# Template register map
Vendor: VendorName Co.Ltd; Series: SeriesName; File version: 1.2
CPU: CM7 r0p1, little endian, MPU, FPU, 4 interrupt priority bits
Registers are 32-bit, read-write, no defined reset value unless marked. A register's access mark holds for its fields unless they carry their own. Offsets are from the block's base; [hi:lo] are bit positions; {n}, {i} and the like mark numbered series; 'fields as' and 'values as' point back to an identical list.

## EPWM1 — Enhanced Pulse Width Modulator 1
Base 0x40000000
Same registers: EPWM{n} {0x3FFFF000+0x1000*n} (n=2..18)
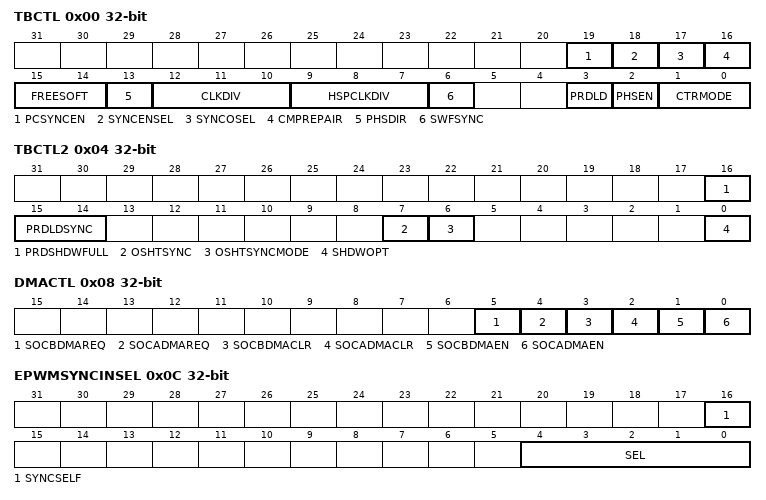
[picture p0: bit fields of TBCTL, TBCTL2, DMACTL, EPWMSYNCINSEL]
0x00 TBCTL — EPWM time base control register
  [19] PCSYNCEN — EPWM PCSYNCEN bit: PWM chopper synchronization enable
  [18] SYNCENSEL — EPWM SYNCENSEL bit: synchronization load enable selection
  [17] SYNCOSEL — EPWM SYNCOSEL bit: EPWM synchronization output enable selection
  [16] CMPREPAIR — EPWM CMPREPAIR bit: PWM wave adjust when phase loading or comparation value updating
  [15:14] FREESOFT — EPWM FREESOFT[1:0] bit: emulation mode bits
  [13] PHSDIR — EPWM PHSDIR bit: phase direction bit
  [12:10] CLKDIV — EPWM CLKDIV[2:0] bit: time base clock prescale bits
  [9:7] HSPCLKDIV — EPWM HSPCLKDIV[2:0] bit: high speed time base clock prescale bits
  [6] SWFSYNC wo — EPWM SWFSYNC bit: software forced sync pulse
  [3] PRDLD — EPWM PRDLD bit: active period register load from shadow select
  [2] PHSEN — EPWM PHSEN bit: counter value load from phase register enable
  [1:0] CTRMODE — EPWM CTRMODE[1:0] bit: counter mode
0x04 TBCTL2 — EPWM time base control register 2
  [16] PRDSHDWFULL ro — EPWM PRDSHDWFULL bit: shadow to active period register full status flag
  [15:14] PRDLDSYNC — EPWM PRDLDSYNC[1:0] bit: shadow to active period register load on sync event
  [7] OSHTSYNC wo — EPWM OSHTSYNC bit: oneshot sync bit
  [6] OSHTSYNCMODE — EPWM OSHTSYNCMODE bit: oneshot sync enable bit
  [0] SHDWOPT — EPWM SHDWOPT bit: counter load period register option
0x08 DMACTL — EPWM DMA register
  [5] SOCBDMAREQ ro — EPWM SOCBDMAREQ bit: SOCBDMA request
  [4] SOCADMAREQ ro — EPWM SOCADMAREQ bit: SOCADMA request
  [3] SOCBDMACLR wo — EPWM SOCBDMACLR bit: SOCBDMA request software clear
  [2] SOCADMACLR wo — EPWM SOCADMACLR bit: SOCADMA request software clear
  [1] SOCBDMAEN — EPWM SOCBDMAEN bit: SOCBDMA enable
  [0] SOCADMAEN — EPWM SOCADMAEN bit: SOCADMA enable
0x0C EPWMSYNCINSEL — EPWM synchronization source selection register
  [16] SYNCSELF — EPWM SYNCSELF bit: EPWMxSYNOUT source sync oneself enable
  [4:0] SEL — EPWM SEL[4:0] bit: EPWMxSYNCI source select
0x10 TBCTR — EPWM time base register
  [15:0] TBCTR — EPWM TBCTR[15:0] bit: time base counter register
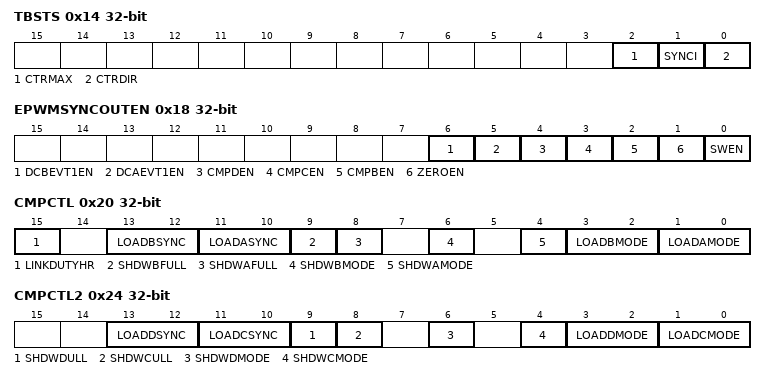
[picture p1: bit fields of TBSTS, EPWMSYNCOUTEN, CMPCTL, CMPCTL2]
0x14 TBSTS — EPWM time base state register
  [2] CTRMAX — EPWM CTRMAX bit: time-base counter max latched status bit
  [1] SYNCI — EPWM SYNCI bit: input synchronization latched status bit
  [0] CTRDIR ro — EPWM CTRDIR bit: time base counter direction status bit
0x18 EPWMSYNCOUTEN — EPWM synchronization output enable register
  [6] DCBEVT1EN — EPWM DCBEVT1EN bit: DCBEVT1.sync event enable
  [5] DCAEVT1EN — EPWM DCAEVT1EN bit: DCAEVT1.sync event enable
  [4] CMPDEN — EPWM CMPDEN bit: enable the TBCTR=CMPD event
  [3] CMPCEN — EPWM CMPCEN bit: enable the TBCTR=CMPC event
  [2] CMPBEN — EPWM CMPBEN bit: enable the TBCTR=CMPB event
  [1] ZEROEN — EPWM ZEROEN bit: enable the TBCTR=0x0000 event
  [0] SWEN — EPWM SWEN bit: TBCTL.SWFSYNC event enable
0x1C TBCTL3 — EPWM time base control register 3
  [0] OSSFRCEN — EPWM OSSFRCEN bit: determines which bit sets the EPWMxSYNCOUT one shot latch
0x20 CMPCTL — EPWM compare control register
  [15] LINKDUTYHR — EPWM LINKDUTYHR bit: CMPAHR and CMPBHR register linking
  [13:12] LOADBSYNC — EPWM LOADBSYNC[1:0] bit: shadow to active CMPB register load on SYNC event
  [11:10] LOADASYNC — EPWM LOADASYNC[1:0] bit: shadow to active CMPA register load on SYNC event
  [9] SHDWBFULL ro — EPWM SHDWBFULL bit: CMPB shadow register full status flag
  [8] SHDWAFULL ro — EPWM SHDWAFULL bit: CMPA shadow register full status flag
  [6] SHDWBMODE — EPWM SHDWBMODE bit: CMPB register operating mode
  [4] SHDWAMODE — EPWM SHDWAMODE bit: CMPA register operating mode
  [3:2] LOADBMODE — EPWM LOADBMODE[1:0] bit: CMPB load from shadow select mode
  [1:0] LOADAMODE — EPWM LOADAMODE[1:0] bit: CMPA load from shadow select mode
0x24 CMPCTL2 — EPWM compare control register 2
  [13:12] LOADDSYNC — EPWM LOADDSYNC[1:0] bit: shadow to active CMPD register load on SYNC event
  [11:10] LOADCSYNC — EPWM LOADCSYNC[1:0] bit: shadow to active CMPC register load on SYNC event
  [9] SHDWDULL ro — EPWM SHDWDULL bit: CMPD shadow register full status flag
  [8] SHDWCULL ro — EPWM SHDWCULL bit: CMPC shadow register full status flag
  [6] SHDWDMODE — EPWM SHDWDMODE bit: CMPD register operating mode
  [4] SHDWCMODE — EPWM SHDWCMODE bit: CMPC register operating mode
  [3:2] LOADDMODE — EPWM LOADDMODE[1:0] bit: CMPD load from shadow select mode
  [1:0] LOADCMODE — EPWM LOADCMODE[1:0] bit: CMPC load from shadow select mode
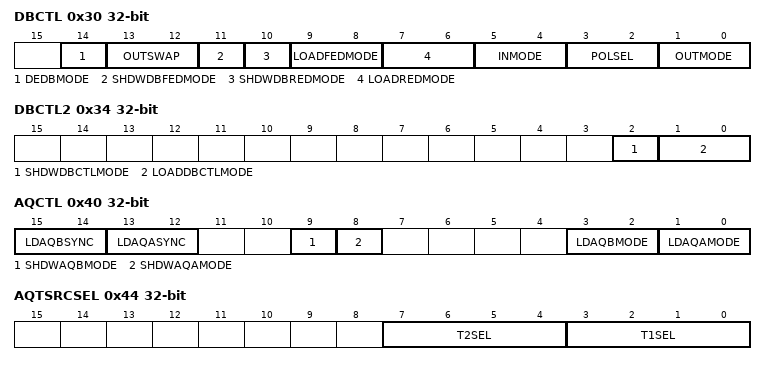
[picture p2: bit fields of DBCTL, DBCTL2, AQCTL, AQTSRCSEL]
0x30 DBCTL — EPWM dead time register
  [14] DEDBMODE — EPWM DEDBMODE bit: dead band dual-edge B mode control
  [13:12] OUTSWAP — EPWM OUTSWAP[1:0] bit: dead band output swap control
  [11] SHDWDBFEDMODE — EPWM SHDWDBFEDMODE bit: FED dead-band load mode
  [10] SHDWDBREDMODE — EPWM SHDWDBREDMODE bit: RED dead-band load mode
  [9:8] LOADFEDMODE — EPWM LOADFEDMODE[1:0] bit: active DBFED load from shadow select mode
  [7:6] LOADREDMODE — EPWM LOADREDMODE[1:0] bit: active DBRED load from shadow select mode
  [5:4] INMODE — EPWM INMODE[1:0] bit: dead-band input mode control
  [3:2] POLSEL — EPWM POLSEL[1:0] bit: polarity select control
  [1:0] OUTMODE — EPWM OUTMODE[1:0] bit: dead-band output mode control
0x34 DBCTL2 — EPWM dead time register 2
  [2] SHDWDBCTLMODE — EPWM SHDWDBCTLMODE bit: DBCTL load mode
  [1:0] LOADDBCTLMODE — EPWM LOADDBCTLMODE[1:0] bit: active DBCTL load from shadow select mode
0x40 AQCTL — EPWM action limitation control register
  [15:14] LDAQBSYNC — EPWM LDAQBSYNC[1:0] bit: shadow to active AQCTLB register load on SYNC event
  [13:12] LDAQASYNC — EPWM LDAQASYNC[1:0] bit: shadow to active AQCTLA register load on SYNC event
  [9] SHDWAQBMODE — EPWM SHDWAQBMODE bit: action qualifier B register operating mode
  [8] SHDWAQAMODE — EPWM SHDWAQAMODE bit: action qualifier A register operating mode
  [3:2] LDAQBMODE — EPWM LDAQBMODE[1:0] bit: active action qualifier B load from shadow select mode
  [1:0] LDAQAMODE — EPWM LDAQAMODE[1:0] bit: active action qualifier A load from shadow select mode
0x44 AQTSRCSEL — EPWM action limitation trigger source selection register
  [7:4] T2SEL — EPWM T2SEL[3:0] bit: T2 event source select bits
  [3:0] T1SEL — EPWM T1SEL[3:0] bit: T1 event source select bits
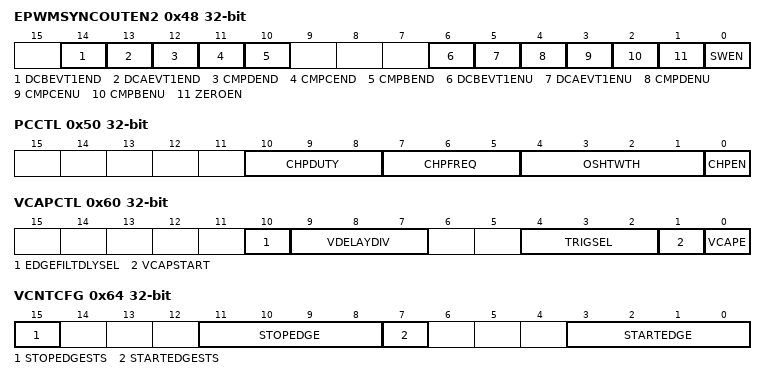
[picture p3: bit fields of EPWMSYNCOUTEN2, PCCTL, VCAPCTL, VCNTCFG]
0x48 EPWMSYNCOUTEN2 — EPWM synchronization output enable register 2
  [14] DCBEVT1END — EPWM DCBEVT1END bit: DCBEVT1.sync event end
  [13] DCAEVT1END — EPWM DCAEVT1END bit: DCAEVT1.sync event end
  [12] CMPDEND — EPWM CMPDEND bit: the TBCTR=CMPD event end
  [11] CMPCEND — EPWM CMPCEND bit: the TBCTR=CMPC event end
  [10] CMPBEND — EPWM CMPBEND bit: the TBCTR=CMPB event end
  [6] DCBEVT1ENU — EPWM DCBEVT1ENU bit: DCBEVT1.sync event enable
  [5] DCAEVT1ENU — EPWM DCAEVT1ENU bit: DCAEVT1.sync event enable
  [4] CMPDENU — EPWM CMPDENU bit: the TBCTR=CMPD event enable
  [3] CMPCENU — EPWM CMPCENU bit: the TBCTR=CMPC event enable
  [2] CMPBENU — EPWM CMPBENU bit: the TBCTR=CMPB event enable
  [1] ZEROEN — EPWM ZEROEN bit: enable the TBCTR=0x0000 event
  [0] SWEN — EPWM SWEN bit: TBCTL.SWFSYNC event enable
0x50 PCCTL — EPWM chopper control register
  [10:8] CHPDUTY — EPWM CHPDUTY[2:0] bit: chopping clock duty cycle
  [7:5] CHPFREQ — EPWM CHPFREQ[2:0] bit: chopping clock frequency division
  [4:1] OSHTWTH — EPWM OSHTWTH[3:0] bit: oneshot pulse width
  [0] CHPEN — EPWM CHPEN bit: PWM-chopping enable
0x60 VCAPCTL — EPWM valley capture control register
  [10] EDGEFILTDLYSEL — EPWM EDGEFILTDLYSEL bit: valley switching mode delay selection
  [9:7] VDELAYDIV — EPWM VDELAYDIV[2:0] bit: valley delay mode divide enable
  [4:2] TRIGSEL — EPWM TRIGSEL[2:0] bit: status of numbered of captured events
  [1] VCAPSTART wo — EPWM VCAPSTART bit: valley capture start control
  [0] VCAPE — EPWM VCAPE bit: valley capture enable bit
0x64 VCNTCFG — EPWM valley counter control register
  [15] STOPEDGESTS ro — EPWM STOPEDGESTS bit: stop edge status bit
  [11:8] STOPEDGE — EPWM STOPEDGE[3:0] bit: counter stop edge selection
  [7] STARTEDGESTS ro — EPWM STARTEDGESTS bit: start edge status bit
  [3:0] STARTEDGE — EPWM STARTEDGE[3:0] bit: counter start edge selection
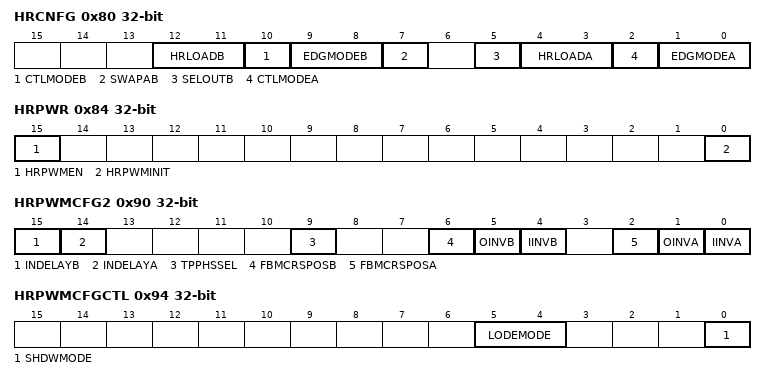
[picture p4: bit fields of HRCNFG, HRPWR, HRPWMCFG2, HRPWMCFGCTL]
0x80 HRCNFG — EPWM HRPWM control register
  [12:11] HRLOADB — EPWM HRLOADB[1:0] bit: shadow mode bit B
  [10] CTLMODEB — EPWM CTLMODEB bit: control mode bits B
  [9:8] EDGMODEB — EPWM EDGMODEB[1:0] bit: edge mode bits B
  [7] SWAPAB — EPWM SWAPAB bit: swap ePWM A & B output signals
  [5] SELOUTB — EPWM SELOUTB bit: EPWMxB output select bit
  [4:3] HRLOADA — EPWM HRLOADA[1:0] bit: shadow mode bit A
  [2] CTLMODEA — EPWM CTLMODEA bit: control mode bits A
  [1:0] EDGMODEA — EPWM EDGMODEA[1:0] bit: edge mode bits A
0x84 HRPWR — EPWM HRPWM enable register
  [15] HRPWMEN — EPWM HRPWMEN bit: high precision PWM function enable
  [0] HRPWMINIT — EPWM HRPWMINIT bit: HRPWM initialize
0x8C TBPRDHR — EPWM high-precision period register
  [5:0] TBPRDHR — EPWM TBPRDHR[5:0] bit: period high precision value
0x90 HRPWMCFG2 — EPWM HRPWM config register 2
  [15] INDELAYB — EPWM INDELAYB bit: channel B input or delay EPWM signal selection
  [14] INDELAYA — EPWM INDELAYA bit: channel A input or delay EPWM signal selection
  [9] TPPHSSEL — EPWM TPPHSSEL bit: period high-precision channel feedback signal selection
  [6] FBMCRSPOSB — EPWM FBMCRSPOSB bit: EPWMxB high-precision channel feedback signal rising edge selection
  [5] OINVB — EPWM OINVB bit: EPWMxB high-precision channel output signal inversion selection
  [4] IINVB — EPWM IINVB bit: EPWMxB high-precision channel input signal inversion selection
  [2] FBMCRSPOSA — EPWM FBMCRSPOSA bit: EPWMxA high-precision channel feedback signal rising edge selection
  [1] OINVA — EPWM OINVA bit: EPWMxA high-precision channel output signal inversion selection
  [0] IINVA — EPWM IINVA bit: EPWMxA high-precision channel input signal inversion selection
0x94 HRPWMCFGCTL — EPWM HRPWM config register
  [5:4] LODEMODE — EPWM LODEMODE[1:0] bit: loading mode select
  [0] SHDWMODE — EPWM SHDWMODE bit: TBPRDHR register operate mode
0x98 HRMSTEP — EPWM HRPWM step register
  [5:0] HRMSTEP — EPWM HRMSTEP[5:0] bit: high precision PWM ware MEP step register
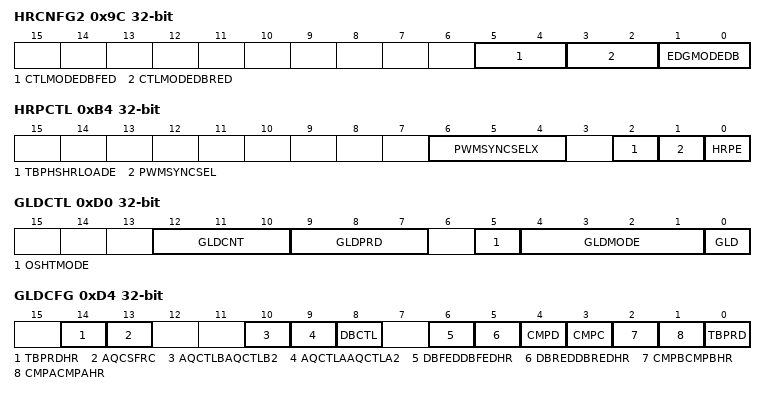
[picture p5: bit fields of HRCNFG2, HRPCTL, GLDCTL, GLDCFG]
0x9C HRCNFG2 — EPWM HRPWM control register 2
  [5:4] CTLMODEDBFED — EPWM CTLMODEDBFED[1:0] bit: DBFEDHR shadow mode control bit
  [3:2] CTLMODEDBRED — EPWM CTLMODEDBRED[1:0] bit: DBREDHR shadow mode control bit
  [1:0] EDGMODEDB — EPWM EDGMODEDB[1:0] bit: dead zone high precision edge mode bits
0xB4 HRPCTL — EPWM HRPWM period control register
  [6:4] PWMSYNCSELX — EPWM PWMSYNCSELX[2:0] bit: extended selection bits for EPWMSYNCPER
  [2] TBPHSHRLOADE — EPWM TBPHSHRLOADE bit: TBPHSHR load enable
  [1] PWMSYNCSEL — EPWM PWMSYNCSEL bit: PWMSYNC source select bit
  [0] HRPE — EPWM HRPE bit: high resolution period enable bit
0xD0 GLDCTL — EPWM global load control register
  [12:10] GLDCNT ro — EPWM GLDCNT[2:0] bit: global load strobe counter register
  [9:7] GLDPRD — EPWM GLDPRD[2:0] bit: global load strobe period select register
  [5] OSHTMODE — EPWM OSHTMODE bit: one shot load mode control bit
  [4:1] GLDMODE — EPWM GLDMODE[3:0] bit: global load pulse selection for shadow to active mode reloads
  [0] GLD — EPWM GLD bit: global shadow to active load event control
0xD4 GLDCFG — EPWM global load config register
  [14] TBPRDHR — EPWM TBPRDHR bit: global load event configuration for TBPRDHR
  [13] AQCSFRC — EPWM AQCSFRC bit: global load event configuration for AQCSFRC
  [10] AQCTLBAQCTLB2 — EPWM AQCTLBAQCTLB2 bit: global load event configuration for AQCTLBAQCTLB2
  [9] AQCTLAAQCTLA2 — EPWM AQCTLAAQCTLA2 bit: global load event configuration for AQCTLAAQCTLA2
  [8] DBCTL — EPWM DBCTL bit: global load event configuration for DBCTL
  [6] DBFEDDBFEDHR — EPWM DBFEDDBFEDHR bit: global load event configuration for DBFEDDBFEDHR
  [5] DBREDDBREDHR — EPWM DBREDDBREDHR bit: global load event configuration for DBREDDBREDHR
  [4] CMPD — EPWM CMPD bit: global load event configuration for CMPD
  [3] CMPC — EPWM CMPC bit: global load event configuration for CMPC
  [2] CMPBCMPBHR — EPWM CMPBCMPBHR bit: global load event configuration for CMPBCMPBHR
  [1] CMPACMPAHR — EPWM CMPACMPAHR bit: global load event configuration for CMPACMPAHR
  [0] TBPRD — EPWM TBPRD bit: global load event configuration for TBPRD
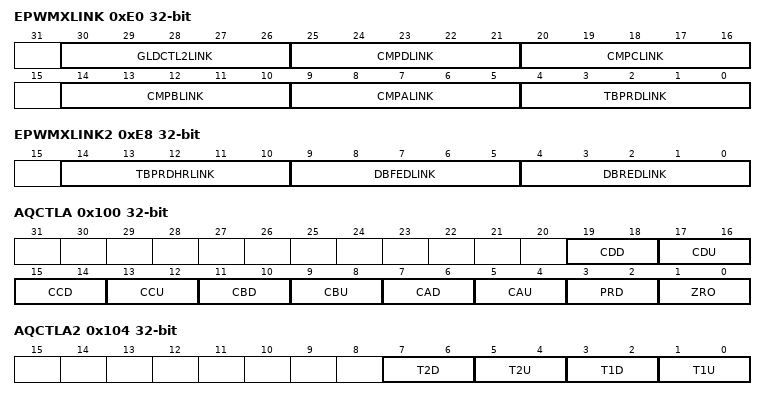
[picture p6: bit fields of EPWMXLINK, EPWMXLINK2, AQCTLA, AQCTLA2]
0xE0 EPWMXLINK — EPWM x linker register
  [30:26] GLDCTL2LINK — EPWM GLDCTL2LINK[4:0] bit: GLDCTL2 link bits
  [25:21] CMPDLINK — EPWM CMPDLINK[4:0] bit: CMPD link bits
  [20:16] CMPCLINK — EPWM CMPCLINK[4:0] bit: CMPC link bits
  [14:10] CMPBLINK — EPWM CMPBLINK[4:0] bit: CMPB link bits
  [9:5] CMPALINK — EPWM CMPALINK[4:0] bit: CMPA link bits
  [4:0] TBPRDLINK — EPWM TBPRDLINK[4:0] bit: TBPRD link bits
0xE8 EPWMXLINK2 — EPWM x linker register 2
  [14:10] TBPRDHRLINK — EPWM TBPRDHRLINK[4:0] bit: TBPRDHR link bits
  [9:5] DBFEDLINK — EPWM DBFEDLINK[4:0] bit: DBFED_DBFEDHR link bits
  [4:0] DBREDLINK — EPWM DBREDLINK[4:0] bit: DBRED_DBREDHR link bits
0x100 AQCTLA — EPWM x A channel limition control register
  [19:18] CDD — EPWM CDD[1:0] bit: action when TBCTR=CMPD on down count
  [17:16] CDU — EPWM CDU[1:0] bit: action when TBCTR=CMPD on up count
  [15:14] CCD — EPWM CCD[1:0] bit: action when TBCTR=CMPC on down count
  [13:12] CCU — EPWM CCU[1:0] bit: action when TBCTR=CMPC on up count
  [11:10] CBD — EPWM CBD[1:0] bit: action when TBCTR=CMPB on down count
  [9:8] CBU — EPWM CBU[1:0] bit: action when TBCTR=CMPB on up count
  [7:6] CAD — EPWM CAD[1:0] bit: action when TBCTR=CMPA on down count
  [5:4] CAU — EPWM CAU[1:0] bit: action when TBCTR=CMPA on up count
  [3:2] PRD — EPWM PRD[1:0] bit: action when TBCTR=TBPRD
  [1:0] ZRO — EPWM ZRO[1:0] bit: action when TBCTR=0
0x104 AQCTLA2 — EPWM x A channel limition control register 2
  [7:6] T2D — EPWM T2D[1:0] bit: action when event occurs on T2 in DOWN-count
  [5:4] T2U — EPWM T2U[1:0] bit: action when event occurs on T2 in UP-count
  [3:2] T1D — EPWM T1D[1:0] bit: action when event occurs on T1 in DOWN-count
  [1:0] T1U — EPWM T1U[1:0] bit: action when event occurs on T1 in UP-count
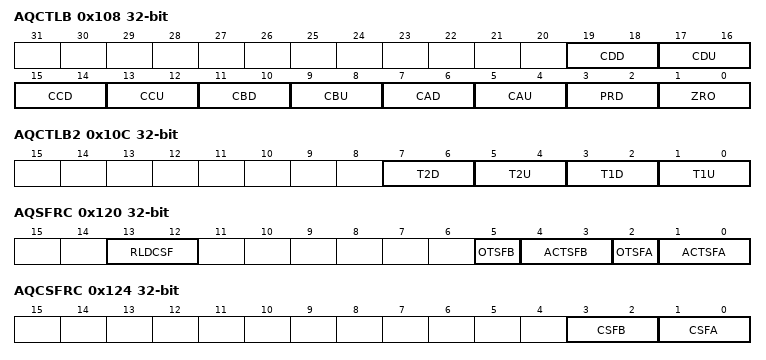
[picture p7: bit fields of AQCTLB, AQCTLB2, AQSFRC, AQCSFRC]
0x108 AQCTLB — EPWM x B channel limition control register
  fields as AQCTLA
0x10C AQCTLB2 — EPWM x B channel limition control register 2
  fields as AQCTLA2
0x120 AQSFRC — EPWM software-forced action limitation register
  [13:12] RLDCSF — EPWM RLDCSF[1:0] bit: AQCSFRC active register reload from shadow options
  [5] OTSFB — EPWM OTSFB bit: one-time software forced event on output B
  [4:3] ACTSFB — EPWM ACTSFB[1:0] bit: action when one-time software force B is invoked
  [2] OTSFA — EPWM OTSFA bit: one-time software forced event on output A
  [1:0] ACTSFA — EPWM ACTSFA[1:0] bit: action when one-time software force A is invoked
0x124 AQCSFRC — EPWM sequential software-forced action limitation register
  [3:2] CSFB — EPWM CSFB[1:0] bit: continuous software force on output B
  [1:0] CSFA — EPWM CSFA[1:0] bit: continuous software force on output A
0x140 DBREDHR — EPWM dead time rising edge high-precision delay register
  [13:8] DBREDHR — EPWM DBREDHR[5:0] bit: dead band rising edge delay high resolution bits
0x144 DBRED — EPWM dead time rising edge delay register 1
  [13:0] DBRED — EPWM DBRED[13:0] bit: rising edge delay value
0x148 DBFEDHR — EPWM dead time falling edge high-precision delay register
  [13:8] DBFEDHR — EPWM DBFEDHR[5:0] bit: dead band falling edge delay high resolution bits
0x14C DBFED — EPWM dead time falling edge delay register 1
  [13:0] DBFED — EPWM DBFED[13:0] bit: falling edge delay count
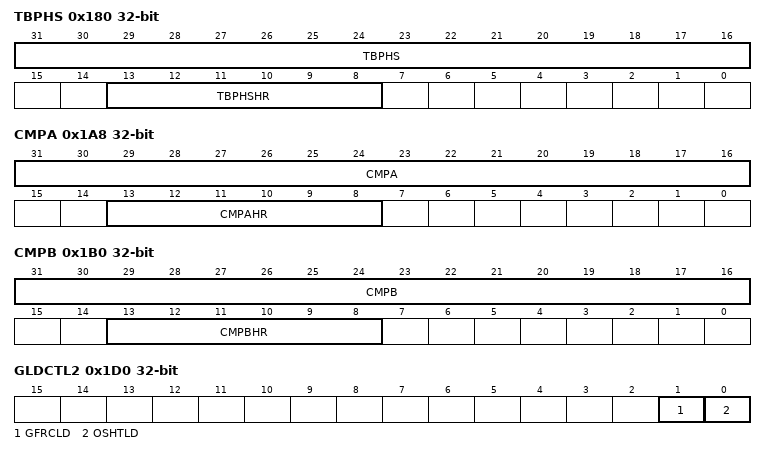
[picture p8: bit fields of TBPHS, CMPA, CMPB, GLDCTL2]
0x180 TBPHS — EPWM time base phase offset register
  [31:16] TBPHS — EPWM TBPHS[15:0] bit: phase offset register
  [13:8] TBPHSHR — EPWM TBPHSHR[5:0] bit: phase offset high resolution register
0x18C TBPRD — EPWM time base period register
  [15:0] TBPRD — EPWM TBPRD[15:0] bit: time base period register
0x1A8 CMPA — EPWM compare A register
  [31:16] CMPA — EPWM CMPA[15:0] bit: compare A register
  [13:8] CMPAHR — EPWM CMPAHR[5:0] bit: compare A HRPWM extension register
0x1B0 CMPB — EPWM compare B register
  [31:16] CMPB — EPWM CMPB[15:0] bit: compare B register
  [13:8] CMPBHR — EPWM CMPBHR[5:0] bit: compare B high resolution bits
0x1BC CMPC — EPWM compare C register
  [15:0] CMPC — EPWM CMPC[15:0] bit: compare C register
0x1C4 CMPD — EPWM compare D register
  [15:0] CMPD — EPWM CMPD[15:0] bit: compare D register
0x1D0 GLDCTL2 — EPWM global load control register 2
  [1] GFRCLD — EPWM GFRCLD bit: force load event in one shot mode
  [0] OSHTLD — EPWM OSHTLD bit: enable reload event in one shot mode
0x1DC SWVDELVAL — EPWM valley software delay register
  [15:0] SWDELVAL — EPWM SWDELVAL[15:0] bit: software valley delay value register
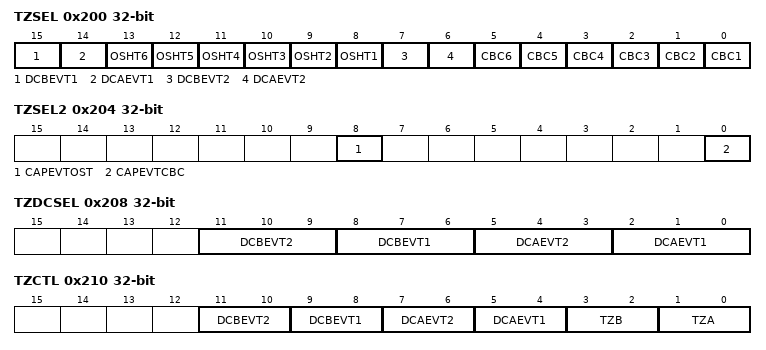
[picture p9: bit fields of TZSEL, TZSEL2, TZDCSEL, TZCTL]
0x200 TZSEL — EPWM trip zone selection register
  [15] DCBEVT1 — EPWM DCBEVT1 bit: digital compare output B event 1 select
  [14] DCAEVT1 — EPWM DCAEVT1 bit: digital compare output A event 1 select
  [n+7] OSHT{n} (n=1..6) — EPWM OSHT{n} bit: trip-zone {n} enable select as one-shot trip event source
  [7] DCBEVT2 — EPWM DCBEVT2 bit: digital compare output B event 2 select
  [6] DCAEVT2 — EPWM DCAEVT2 bit: digital compare output A event 2 select
  [n-1] CBC{n} (n=1..6) — EPWM CBC{n} bit: trip-zone {n} enable select as CBC trip event source
0x204 TZSEL2 — EPWM trip zone selection register 2
  [8] CAPEVTOST — EPWM CAPEVTOST bit: CAPEVT OST select
  [0] CAPEVTCBC — EPWM CAPEVTCBC bit: CAPEVT CBC mode select
0x208 TZDCSEL — EPWM trip zone digital compare register
  [11:9] DCBEVT2 — EPWM DCBEVT2[2:0] bit: digital compare output B event 2 selection
  [8:6] DCBEVT1 — EPWM DCBEVT1[2:0] bit: digital compare output B event 1 selection
  [5:3] DCAEVT2 — EPWM DCAEVT2[2:0] bit: digital compare output A event 2 selection
  [2:0] DCAEVT1 — EPWM DCAEVT1[2:0] bit: digital compare output A event 1 selection
0x210 TZCTL — EPWM trip zone control register
  [11:10] DCBEVT2 — EPWM DCBEVT2[1:0] bit: digital compare output B event 2 action on EPWMxB
  [9:8] DCBEVT1 — EPWM DCBEVT1[1:0] bit: digital compare output B event 1 action on EPWMxB
  [7:6] DCAEVT2 — EPWM DCAEVT2[1:0] bit: digital compare output A event 2 action on EPWMxA
  [5:4] DCAEVT1 — EPWM DCAEVT1[1:0] bit: digital compare output A event 1 action on EPWMxA
  [3:2] TZB — EPWM TZB[1:0] bit: TZ1 to TZ6 trip action on EPWMxB
  [1:0] TZA — EPWM TZA[1:0] bit: TZ1 to TZ6 trip action on EPWMxA
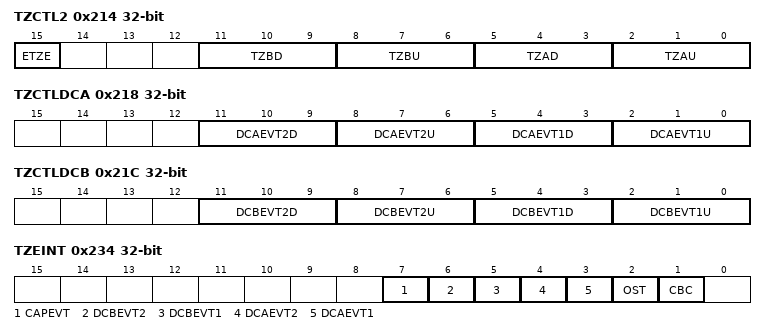
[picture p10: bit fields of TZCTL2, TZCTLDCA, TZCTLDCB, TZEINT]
0x214 TZCTL2 — EPWM trip zone control register 2
  [15] ETZE — EPWM ETZE bit: TZCTL2 enable
  [11:9] TZBD — EPWM TZBD[2:0] bit: TZ1 to TZ6 trip action on EPWMxB while count direction is DOWN
  [8:6] TZBU — EPWM TZBU[2:0] bit: TZ1 to TZ6 trip action on EPWMxB while count direction is UP
  [5:3] TZAD — EPWM TZAD[2:0] bit: TZ1 to TZ6 trip action on EPWMxA while count direction is DOWN
  [2:0] TZAU — EPWM TZAU[2:0] bit: TZ1 to TZ6 trip action on EPWMxA while count direction is UP
0x218 TZCTLDCA — EPWM trip zone digital compare A register
  [11:9] DCAEVT2D — EPWM DCAEVT2D[2:0] bit: DCAEVT2 action on EPWMxA while count direction is DOWN
  [8:6] DCAEVT2U — EPWM DCAEVT2U[2:0] bit: DCAEVT2 action on EPWMxA while count direction is UP
  [5:3] DCAEVT1D — EPWM DCAEVT1D[2:0] bit: DCAEVT1 action on EPWMxA while count direction is DOWN
  [2:0] DCAEVT1U — EPWM DCAEVT1U[2:0] bit: DCAEVT1 action on EPWMxA while count direction is UP
0x21C TZCTLDCB — EPWM trip zone digital compare B register
  [11:9] DCBEVT2D — EPWM DCBEVT2D[2:0] bit: DCBEVT2 action on EPWMxB while count direction is DOWN
  [8:6] DCBEVT2U — EPWM DCBEVT2U[2:0] bit: DCBEVT2 action on EPWMxB while count direction is UP
  [5:3] DCBEVT1D — EPWM DCBEVT1D[2:0] bit: DCBEVT1 action on EPWMxB while count direction is DOWN
  [2:0] DCBEVT1U — EPWM DCBEVT1U[2:0] bit: DCBEVT1 action on EPWMxB while count direction is UP
0x234 TZEINT — EPWM trip zone interrupt enable register
  [7] CAPEVT — EPWM CAPEVT bit: capture event interrupt enable
  [6] DCBEVT2 — EPWM DCBEVT2 bit: digital compare output B event 2 interrupt enable
  [5] DCBEVT1 — EPWM DCBEVT1 bit: digital compare output B event 1 interrupt enable
  [4] DCAEVT2 — EPWM DCAEVT2 bit: digital compare output A event 2 interrupt enable
  [3] DCAEVT1 — EPWM DCAEVT1 bit: digital compare output A event 1 interrupt enable
  [2] OST — EPWM OST bit: trip-zone one-shot interrupt enable
  [1] CBC — EPWM CBC bit: trip-zone cycle-by-cycle interrupt enable
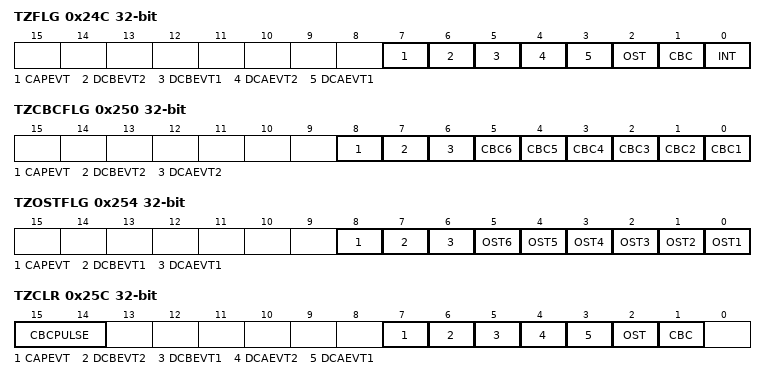
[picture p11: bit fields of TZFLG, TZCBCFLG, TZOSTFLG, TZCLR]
0x24C TZFLG ro — EPWM trip zone flag register
  [7] CAPEVT — EPWM CAPEVT bit: latched status flag for capture event
  [6] DCBEVT2 — EPWM DCBEVT2 bit: latched status flag for digital compare output B event 2
  [5] DCBEVT1 — EPWM DCBEVT1 bit: latched status flag for digital compare output B event 1
  [4] DCAEVT2 — EPWM DCAEVT2 bit: latched status flag for digital compare output A event 2
  [3] DCAEVT1 — EPWM DCAEVT1 bit: latched status flag for digital compare output A event 1
  [2] OST — EPWM OST bit: latched status flag for A one-shot trip event
  [1] CBC — EPWM CBC bit: latched status flag for cycle-by-cycle trip event
  [0] INT — EPWM INT bit: latched trip interrupt status flag
0x250 TZCBCFLG ro — EPWM trip zone CBC flag register
  [8] CAPEVT — EPWM CAPEVT bit: latched status flag for capture event
  [7] DCBEVT2 — EPWM DCBEVT2 bit: latched status flag for digital compare B output event 2 trip latch
  [6] DCAEVT2 — EPWM DCAEVT2 bit: latched status flag for digital compare A output event 2 trip latch
  [n-1] CBC{n} (n=1..6) — EPWM CBC{n} bit: latched status flag for CBC{n} trip latch
0x254 TZOSTFLG ro — EPWM trip zone OST flag register
  [8] CAPEVT — EPWM CAPEVT bit: latched status flag for capture event
  [7] DCBEVT1 — EPWM DCBEVT1 bit: latched status flag for digital compare B output event 1 trip latch
  [6] DCAEVT1 — EPWM DCAEVT1 bit: latched status flag for digital compare A output event 1 trip latch
  [n-1] OST{n} (n=1..6) — EPWM OST{n} bit: latched status flag for OST{n} trip latch
0x25C TZCLR — EPWM trip zone flag clear register
  [15:14] CBCPULSE — EPWM CBCPULSE[1:0] bit: clear pulse for cycle-by-cycle trip latch
  [7] CAPEVT wo — EPWM CAPEVT bit: clear flag for capture event
  [6] DCBEVT2 wo — EPWM DCBEVT2 bit: clear flag for digital compare output B event 2
  [5] DCBEVT1 wo — EPWM DCBEVT1 bit: clear flag for digital compare output B event 1
  [4] DCAEVT2 wo — EPWM DCAEVT2 bit: clear flag for digital compare output A event 2
  [3] DCAEVT1 wo — EPWM DCAEVT1 bit: clear flag for digital compare output A event 1
  [2] OST wo — EPWM OST bit: clear flag for one-shot trip latch
  [1] CBC wo — EPWM CBC bit: clear flag for cycle-by-cycle trip latch
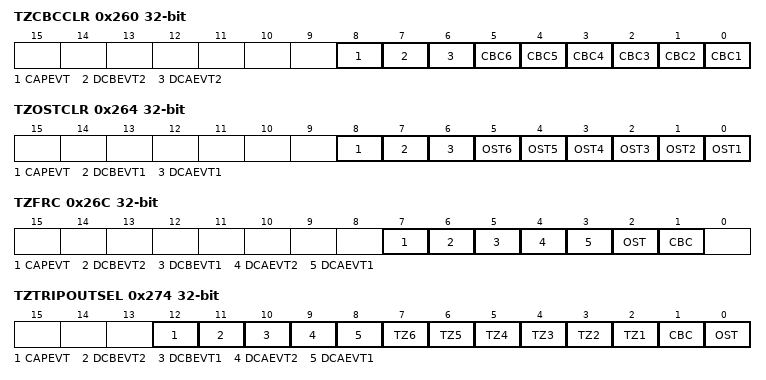
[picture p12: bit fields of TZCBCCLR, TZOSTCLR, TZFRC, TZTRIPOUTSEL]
0x260 TZCBCCLR wo — EPWM trip zone CBC flag clear register
  [8] CAPEVT — EPWM CAPEVT bit: clear flag for CAPEVT selected for CBC
  [7] DCBEVT2 — EPWM DCBEVT2 bit: clear flag for digital compare output B event 2 selected for CBC
  [6] DCAEVT2 — EPWM DCAEVT2 bit: clear flag for digital compare output A event 2 selected for CBC
  [n-1] CBC{n} (n=1..6) — EPWM CBC{n} bit: clear flag for CBC{n} trip latch
0x264 TZOSTCLR wo — EPWM trip zone OST flag clear register
  [8] CAPEVT — EPWM CAPEVT bit: clear flag for CAPEVT selected for OST
  [7] DCBEVT1 — EPWM DCBEVT1 bit: clear flag for digital compare output B event 1 selected for OST
  [6] DCAEVT1 — EPWM DCAEVT1 bit: clear flag for digital compare output A event 1 selected for OST
  [n-1] OST{n} (n=1..6) — EPWM OST{n} bit: clear flag for OST{n} trip latch
0x26C TZFRC — EPWM trip zone software force register
  [7] CAPEVT — EPWM CAPEVT bit: force flag for capture event output
  [6] DCBEVT2 — EPWM DCBEVT2 bit: force flag for digital compare output B event 2
  [5] DCBEVT1 — EPWM DCBEVT1 bit: force flag for digital compare output B event 1
  [4] DCAEVT2 — EPWM DCAEVT2 bit: force flag for digital compare output A event 2
  [3] DCAEVT1 — EPWM DCAEVT1 bit: force flag for digital compare output A event 1
  [2] OST — EPWM OST bit: force a one-shot trip event via software
  [1] CBC — EPWM CBC bit: force a cycle-by-cycle trip event via software
0x274 TZTRIPOUTSEL — EPWM software TRIPOUT selection register
  [12] CAPEVT — EPWM CAPEVT bit: CAPEVT select
  [11] DCBEVT2 — EPWM DCBEVT2 bit: DCBEVT2 select
  [10] DCBEVT1 — EPWM DCBEVT1 bit: DCBEVT1 select
  [9] DCAEVT2 — EPWM DCAEVT2 bit: DCAEVT2 select
  [8] DCAEVT1 — EPWM DCAEVT1 bit: DCAEVT1 select
  [n+1] TZ{n} (n=1..6) — EPWM TZ{n} bit: TZ{n} select
  [1] CBC — EPWM CBC bit: CBC select
  [0] OST — EPWM OST bit: OST select
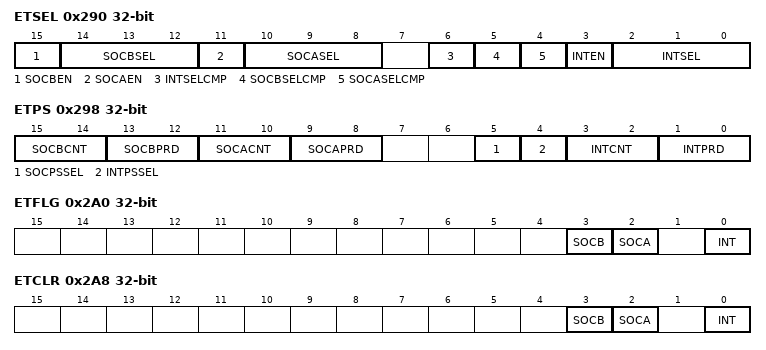
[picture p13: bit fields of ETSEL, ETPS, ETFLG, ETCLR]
0x290 ETSEL — EPWM event trigger seletion register
  [15] SOCBEN — EPWM SOCBEN bit: EPWMxSOCB enable
  [14:12] SOCBSEL — EPWM SOCBSEL[2:0] bit: EPWMxSOCB source event selection
  [11] SOCAEN — EPWM SOCAEN bit: EPWMxSOCA enable
  [10:8] SOCASEL — EPWM SOCASEL[2:0] bit: EPWMxSOCA source event selection
  [6] INTSELCMP — EPWM INTSELCMP bit: EPWMxINT compare register selection
  [5] SOCBSELCMP — EPWM SOCBSELCMP bit: EPWMxSOCB compare register selection
  [4] SOCASELCMP — EPWM SOCASELCMP bit: EPWMxSOCA compare register selection
  [3] INTEN — EPWM INTEN bit: EPWM interrupt enable
  [2:0] INTSEL — EPWM INTSEL[2:0] bit: EPWM interrupt source event selection
0x298 ETPS — EPWM event trigger scaling register
  [15:14] SOCBCNT ro — EPWM SOCBCNT[1:0] bit: EPWM ADC start-of-conversion B event counter register
  [13:12] SOCBPRD — EPWM SOCBPRD[1:0] bit: EPWM ADC start-of-conversion B event period select
  [11:10] SOCACNT ro — EPWM SOCACNT[1:0] bit: EPWM ADC start-of-conversion A event counter register
  [9:8] SOCAPRD — EPWM SOCAPRD[1:0] bit: EPWM ADC start-of-conversion A event period select
  [5] SOCPSSEL — EPWM SOCPSSEL bit: EPWMxSOC A/B prescale selection bits
  [4] INTPSSEL — EPWM INTPSSEL bit: EPWMxINTn prescale selection bits
  [3:2] INTCNT ro — EPWM INTCNT[1:0] bit: EPWM interrupt event counter register
  [1:0] INTPRD — EPWM INTPRD[1:0] bit: EPWM interrupt period select
0x2A0 ETFLG ro — EPWM event trigger flag register
  [3] SOCB — EPWM SOCB bit: EPWMxSOCB status flag
  [2] SOCA — EPWM SOCA bit: EPWMxSOCA status flag
  [0] INT — EPWM INT bit: EPWMx_INT interrupt status flag
0x2A8 ETCLR wo — EPWM event trigger flag clear register
  [3] SOCB — EPWM SOCB bit: EPWMxSOCB status flag clear bit
  [2] SOCA — EPWM SOCA bit: EPWMxSOCA status flag clear bit
  [0] INT — EPWM INT bit: EPWMx_INT interrupt status flag clear bit
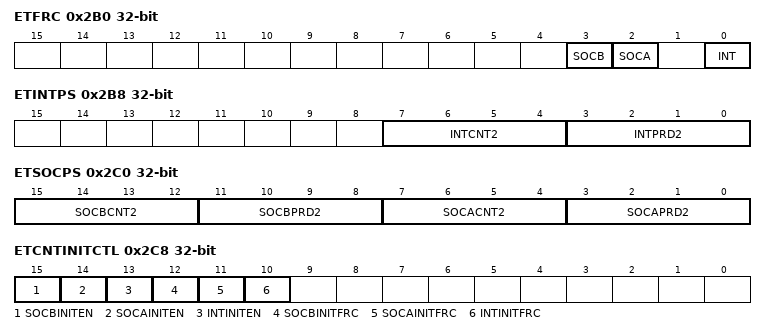
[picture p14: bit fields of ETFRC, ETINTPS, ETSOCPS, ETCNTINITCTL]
0x2B0 ETFRC — EPWM event trigger software force register
  [3] SOCB — EPWM SOCB bit: EPWMxSOCB software force bit
  [2] SOCA — EPWM SOCA bit: EPWMxSOCA software force bit
  [0] INT — EPWM INT bit: EPWMx_INT software force bit
0x2B8 ETINTPS — EPWM event trigger interrupt scaling register
  [7:4] INTCNT2 ro — EPWM INTCNT2[3:0] bit: EPWMINT counter 2
  [3:0] INTPRD2 — EPWM INTPRD2[3:0] bit: EPWMINT period 2 select
0x2C0 ETSOCPS — EPWM event trigger SOC scaling register
  [15:12] SOCBCNT2 ro — EPWM SOCBCNT2[3:0] bit: EPWMxSOCB counter 2
  [11:8] SOCBPRD2 — EPWM SOCBPRD2[3:0] bit: EPWMxSOCB period 2 select
  [7:4] SOCACNT2 ro — EPWM SOCACNT2[3:0] bit: EPWMxSOCA counter 2
  [3:0] SOCAPRD2 — EPWM SOCAPRD2[3:0] bit: EPWMxSOCA period 2 select
0x2C8 ETCNTINITCTL — EPWM event trigger counter initial control register
  [15] SOCBINITEN — EPWM SOCBINITEN bit: EPWMxSOCB counter 2 software initialization enable
  [14] SOCAINITEN — EPWM SOCAINITEN bit: EPWMxSOCA counter 2 software initialization enable
  [13] INTINITEN — EPWM INTINITEN bit: EPWMINT counter 2 software initialization enable
  [12] SOCBINITFRC wo — EPWM SOCBINITFRC bit: EPWMxSOCB counter 2 software initialization force
  [11] SOCAINITFRC wo — EPWM SOCAINITFRC bit: EPWMxSOCA counter 2 software initialization force
  [10] INTINITFRC wo — EPWM INTINITFRC bit: EPWMINT counter 2 software initialization force
0x2D0 ETCNTINIT — EPWM event trigger counter initial register
  [11:8] SOCBINIT — EPWM SOCBINIT[3:0] bit: EPWMxSOCB counter 2 software initialization bits
  [7:4] SOCAINIT — EPWM SOCAINIT[3:0] bit: EPWMxSOCA counter 2 software initialization bits
  [3:0] INTINIT — EPWM INTINIT[3:0] bit: EPWMINT counter 2 software initialization bits
0x2D8 ETINTMIXEN — EPWM event trigger INT selection register
  [16] DCAEVT1SEL — EPWM DCAEVT1SEL bit: DCAEVT1 select as mixed ET interrupt trigger signal
  [10] DCAEVT1 — EPWM DCAEVT1 bit: enable DCAEVT1.inter to the mixed ET interrupt trigger signal
  [9] CDD — EPWM CDD bit: CMPD down-count match enable event enable select to ETINTMIX
  [8] CDU — EPWM CDU bit: CMPD up-count match enable event enable select to ETINTMIX
  [7] CCD — EPWM CCD bit: CMPC down-count match enable event enable select to ETINTMIX
  [6] CCU — EPWM CCU bit: CMPC up-count match enable event enable select to ETINTMIX
  [5] CBD — EPWM CBD bit: CMPB down-count match enable event enable select to ETINTMIX
  [4] CBU — EPWM CBU bit: CMPB up-count match enable event enable select to ETINTMIX
  [3] CAD — EPWM CAD bit: CMPA down-count match enable event enable select to ETINTMIX
  [2] CAU — EPWM CAU bit: CMPA up-count match enable event enable select to ETINTMIX
  [1] PRD — EPWM PRD bit: period match event enable select to ETINTMIX
  [0] ZRO — EPWM ZRO bit: zero match event enable select to ETINTMIX
0x2E0 ETSOCAMIXEN — EPWM event trigger SOCA selection register
  [16] DCAEVT1SEL — EPWM DCAEVT1SEL bit: DCAEVT1 select as mixed ET SOCA trigger signal
  [10] DCAEVT1 — EPWM DCAEVT1 bit: enable DCAEVT1.inter to the mixed ET SOCA trigger signal
  [9] CDD — EPWM CDD bit: CMPD down-count match enable event enable select to ETSOCAMIX
  [8] CDU — EPWM CDU bit: CMPD up-count match enable event enable select to ETSOCAMIX
  [7] CCD — EPWM CCD bit: CMPC down-count match enable event enable select to ETSOCAMIX
  [6] CCU — EPWM CCU bit: CMPC up-count match enable event enable select to ETSOCAMIX
  [5] CBD — EPWM CBD bit: CMPB down-count match enable event enable select to ETSOCAMIX
  [4] CBU — EPWM CBU bit: CMPB up-count match enable event enable select to ETSOCAMIX
  [3] CAD — EPWM CAD bit: CMPA down-count match enable event enable select to ETSOCAMIX
  [2] CAU — EPWM CAU bit: CMPA up-count match enable event enable select to ETSOCAMIX
  [1] PRD — EPWM PRD bit: period match event enable select to ETSOCAMIX
  [0] ZRO — EPWM ZRO bit: zero match event enable select to ETSOCAMIX
0x2E8 ETSOCBMIXEN — EPWM event trigger SOCB selection register
  [16] DCBEVT1SEL — EPWM DCBEVT1SEL bit: DCBEVT1 select as mixed ET SOCB trigger signal
  [10] DCBEVT1 — EPWM DCBEVT1 bit: enable DCBEVT1.inter to the mixed ET SOCB trigger signal
  [9] CDD — EPWM CDD bit: CMPD down-count match enable event enable select to ETSOCBMIX
  [8] CDU — EPWM CDU bit: CMPD up-count match enable event enable select to ETSOCBMIX
  [7] CCD — EPWM CCD bit: CMPC down-count match enable event enable select to ETSOCBMIX
  [6] CCU — EPWM CCU bit: CMPC up-count match enable event enable select to ETSOCBMIX
  [5] CBD — EPWM CBD bit: CMPB down-count match enable event enable select to ETSOCBMIX
  [4] CBU — EPWM CBU bit: CMPB up-count match enable event enable select to ETSOCBMIX
  [3] CAD — EPWM CAD bit: CMPA down-count match enable event enable select to ETSOCBMIX
  [2] CAU — EPWM CAU bit: CMPA up-count match enable event enable select to ETSOCBMIX
  [1] PRD — EPWM PRD bit: period match event enable select to ETSOCBMIX
  [0] ZRO — EPWM ZRO bit: zero match event enable select to ETSOCBMIX
0x300 DCTRIPSEL — EPWM digital compare trip zone seletion register
  [15:12] DCBLCOMPSEL — EPWM DCBLCOMPSEL[3:0] bit: digital compare B low input select bits
  [11:8] DCBHCOMPSEL — EPWM DCBHCOMPSEL[3:0] bit: digital compare B high input select bits
  [7:4] DCALCOMPSEL — EPWM DCALCOMPSEL[3:0] bit: digital compare A low input select bits
  [3:0] DCAHCOMPSEL — EPWM DCAHCOMPSEL[3:0] bit: digital compare A high input select bits
0x30C DCACTL — EPWM digital compare A control register
  [15] EVT2LAT ro — EPWM EVT2LAT bit: indicates the status of DCAEVT2LAT signal
  [14:13] EVT2LATCLRSEL — EPWM EVT2LATCLRSEL[1:0] bit: DCAEVT2 latched clear source select
  [12] EVT2LATSEL — EPWM EVT2LATSEL bit: DCAEVT2 latched signal select
  [9] EVT2FRCSYNCSEL — EPWM EVT2FRCSYNCSEL bit: DCAEVT2 force synchronization signal select
  [8] EVT2SRCSEL — EPWM EVT2SRCSEL bit: DCAEVT2 source signal select
  [7] EVT1LAT ro — EPWM EVT1LAT bit: indicates the status of DCAEVT1LAT signal
  [6:5] EVT1LATCLRSEL — EPWM EVT1LATCLRSEL[1:0] bit: DCAEVT1 latched clear source select
  [4] EVT1LATSEL — EPWM EVT1LATSEL bit: DCAEVT1 latched signal select
  [3] EVT1SYNCE — EPWM EVT1SYNCE bit: DCAEVT1 SYNC enable select
  [2] EVT1SOCE — EPWM EVT1SOCE bit: DCAEVT1 SOC enable select
  [1] EVT1FRCSYNCSEL — EPWM EVT1FRCSYNCSEL bit: DCAEVT1 force synchronization signal select
  [0] EVT1SRCSEL — EPWM EVT1SRCSEL bit: DCAEVT1 source signal select
0x310 DCBCTL — EPWM digital compare B control register
  [15] EVT2LAT ro — EPWM EVT2LAT bit: indicates the status of DCBEVT2LAT signal
  [14:13] EVT2LATCLRSEL — EPWM EVT2LATCLRSEL[1:0] bit: DCBEVT2 latched clear source select
  [12] EVT2LATSEL — EPWM EVT2LATSEL bit: DCBEVT2 latched signal select
  [9] EVT2FRCSYNCSEL — EPWM EVT2FRCSYNCSEL bit: DCBEVT2 force synchronization signal select
  [8] EVT2SRCSEL — EPWM EVT2SRCSEL bit: DCBEVT2 source signal select
  [7] EVT1LAT ro — EPWM EVT1LAT bit: indicates the status of DCBEVT1LAT signal
  [6:5] EVT1LATCLRSEL — EPWM EVT1LATCLRSEL[1:0] bit: DCBEVT1 latched clear source select
  [4] EVT1LATSEL — EPWM EVT1LATSEL bit: DCBEVT1 latched signal select
  [3] EVT1SYNCE — EPWM EVT1SYNCE bit: DCBEVT1 SYNC enable select
  [2] EVT1SOCE — EPWM EVT1SOCE bit: DCBEVT1 SOC enable select
  [1] EVT1FRCSYNCSEL — EPWM EVT1FRCSYNCSEL bit: DCBEVT1 force synchronization signal select
  [0] EVT1SRCSEL — EPWM EVT1SRCSEL bit: DCBEVT1 source signal select
0x31C DCFCTL — EPWM digital compare filter control register
  [15:13] EDGESTATUS ro — EPWM EDGESTATUS[2:0] bit: edge status
  [12:10] EDGECOUNT — EPWM EDGECOUNT[2:0] bit: edge count
  [9:8] EDGEMODE — EPWM EDGEMODE[1:0] bit: edge mode select
  [6] EDGEFILTSEL — EPWM EDGEFILTSEL bit: edge filter select
  [5:4] PULSESEL — EPWM PULSESEL[1:0] bit: pulse select for blanking & capture alignment
  [3] BLANKINV — EPWM BLANKINV bit: blanking window inversion
  [2] BLANKE — EPWM BLANKE bit: blanking window enable select
  [1:0] SRCSEL — EPWM SRCSEL[1:0] bit: filter block signal source select
0x320 DCCAPCTL — EPWM digital compare capture control register
  [15] CAPMODE — EPWM CAPMODE bit: counter capture mode
  [14] CAPCLR wo — EPWM CAPCLR bit: DC capture latched status clear flag
  [13] CAPSTS ro — EPWM CAPSTS bit: latched status flag for capture event
  [1] SHDWMODE — EPWM SHDWMODE bit: TBCTR counter capture shadow select mode
  [0] CAPE — EPWM CAPE bit: TBCTR counter capture enable select
0x324 DCFOFFSET — EPWM digital compare filter offset register
  [15:0] DCFOFFSET — EPWM DCFOFFSET[15:0] bit: blanking window offset
0x328 DCFOFFSETCNT ro — EPWM digital compare filter offset counter register
  [15:0] DCFOFFSETCNT — EPWM DCFOFFSETCNT[15:0] bit: blanking offset counter current value
0x32C DCFWINDOW — EPWM digital compare filter window register
  [15:0] DCFWINDOW — EPWM DCFWINDOW[15:0] bit: blanking window width
0x330 DCFWINDOWCNT ro — EPWM digital compare filter window counter register
  [15:0] DCFWINDOWCNT — EPWM DCFWINDOWCNT[15:0] bit: blanking window counter
0x334 BLANKPULSEMIXSEL — EPWM blank window trigger pulse selection register
  [9] CDD — EPWM CDD bit: CMPD down-count match enable event enable select to BLANKPULSEMIX
  [8] CDU — EPWM CDU bit: CMPD up-count match enable event enable select to BLANKPULSEMIX
  [7] CCD — EPWM CCD bit: CMPC down-count match enable event enable select to BLANKPULSEMIX
  [6] CCU — EPWM CCU bit: CMPC up-count match enable event enable select to BLANKPULSEMIX
  [5] CBD — EPWM CBD bit: CMPB down-count match enable event enable select to BLANKPULSEMIX
  [4] CBU — EPWM CBU bit: CMPB up-count match enable event enable select to BLANKPULSEMIX
  [3] CAD — EPWM CAD bit: CMPA down-count match enable event enable select to BLANKPULSEMIX
  [2] CAU — EPWM CAU bit: CMPA up-count match enable event enable select to BLANKPULSEMIX
  [1] PRD — EPWM PRD bit: period match event enable select to BLANKPULSEMIX
  [0] ZRO — EPWM ZRO bit: zero match event enable select to BLANKPULSEMIX
0x338 DCCAPMIXSEL — EPWM capture trigger pulse selection register
  [9] CDD — EPWM CDD bit: CMPD down-count match enable event enable select to DCCAPMIX
  [8] CDU — EPWM CDU bit: CMPD up-count match enable event enable select to DCCAPMIX
  [7] CCD — EPWM CCD bit: CMPC down-count match enable event enable select to DCCAPMIX
  [6] CCU — EPWM CCU bit: CMPC up-count match enable event enable select to DCCAPMIX
  [5] CBD — EPWM CBD bit: CMPB down-count match enable event enable select to DCCAPMIX
  [4] CBU — EPWM CBU bit: CMPB up-count match enable event enable select to DCCAPMIX
  [3] CAD — EPWM CAD bit: CMPA down-count match enable event enable select to DCCAPMIX
  [2] CAU — EPWM CAU bit: CMPA up-count match enable event enable select to DCCAPMIX
  [1] PRD — EPWM PRD bit: period match event enable select to DCCAPMIX
  [0] ZRO — EPWM ZRO bit: zero match event enable select to DCCAPMIX
0x33C DCCAP ro — EPWM digital compare counter capture register
  [15:0] DCCAP — EPWM DCCAP[15:0] bit: digital compare time-base counter capture
0x348 DCAHTRIPSEL — EPWM digital compare AH trip zone selection register
  [14] TRIPINPUT15 — EPWM TRIPINPUT15 bit: TRIP input 15 whether selected to DCAH
  [13] TRIPINPUT14 — EPWM TRIPINPUT14 bit: TRIP input 14 whether selected to DCAH
  [n-1] TRIPINPUT{n} (n=1..12) — EPWM TRIPINPUT{n} bit: TRIP input {n} whether selected to DCAH
0x34C DCALTRIPSEL — EPWM digital compare AL trip zone selection register
  [14] TRIPINPUT15 — EPWM TRIPINPUT15 bit: TRIP input 15 whether selected to DCAL
  [13] TRIPINPUT14 — EPWM TRIPINPUT14 bit: TRIP input 14 whether selected to DCAL
  [n-1] TRIPINPUT{n} (n=1..12) — EPWM TRIPINPUT{n} bit: TRIP input {n} whether selected to DCAL
0x350 DCBHTRIPSEL — EPWM digital compare BH trip zone selection register
  [14] TRIPINPUT15 — EPWM TRIPINPUT15 bit: TRIP input 15 whether selected to DCBH
  [13] TRIPINPUT14 — EPWM TRIPINPUT14 bit: TRIP input 14 whether selected to DCBH
  [n-1] TRIPINPUT{n} (n=1..12) — EPWM TRIPINPUT{n} bit: TRIP input {n} whether selected to DCBH
0x354 DCBLTRIPSEL — EPWM digital compare BL trip zone selection register
  [14] TRIPINPUT15 — EPWM TRIPINPUT15 bit: TRIP input 15 whether selected to DCBL
  [13] TRIPINPUT14 — EPWM TRIPINPUT14 bit: TRIP input 14 whether selected to DCBL
  [n-1] TRIPINPUT{n} (n=1..12) — EPWM TRIPINPUT{n} bit: TRIP input {n} whether selected to DCBL
0x358 CAPCTL — EPWM event capture control register
  [8] FRCLOAD — EPWM FRCLOAD bit: force load
  [4] PULSECTL — EPWM PULSECTL bit: capture input polarity select mux
  [3] CAPINPOL — EPWM CAPINPOL bit: capture input polarity select mux
  [2:1] CAPGATEPOL — EPWM CAPGATEPOL[1:0] bit: capture gate input polarity select mux
  [0] SRCSEL — EPWM SRCSEL bit: capture logic input select mux
0x35C CAPGATETRIPSEL — EPWM event capture gate-trip selection register
  [14] TRIPINPUT15 — EPWM TRIPINPUT15 bit: TRIP input 15 whether selected to CAPGATE
  [13] TRIPINPUT14 — EPWM TRIPINPUT14 bit: TRIP input 14 whether selected to CAPGATE
  [n-1] TRIPINPUT{n} (n=1..12) — EPWM TRIPINPUT{n} bit: TRIP input {n} whether selected to CAPGATE
0x360 CAPINTRIPSEL — EPWM event capture in-trip selection register
  [14] TRIPINPUT15 — EPWM TRIPINPUT15 bit: TRIP input 15 whether selected to CAPIN
  [13] TRIPINPUT14 — EPWM TRIPINPUT14 bit: TRIP input 14 whether selected to CAPIN
  [n-1] TRIPINPUT{n} (n=1..12) — EPWM TRIPINPUT{n} bit: TRIP input {n} whether selected to CAPIN
0x364 CAPTRIPSEL — EPWM event capture selection register
  [7:4] CAPGATECOMPSEL — EPWM CAPGATECOMPSEL[3:0] bit: digital compare A low input select bits
  [3:0] CAPINCOMPSEL — EPWM CAPINCOMPSEL[3:0] bit: digital compare A high input select bits
0x3E8 EPWMLOCK wo — EPWM locker register
  [31:16] KEY — EPWM KEY[15:0] bit: only when 0xA5A5 is written at the high position can this register be written
  [4] DCLOCK — EPWM DCLOCK bit: digital compare registers locked select
  [3] TZCLRLOCK — EPWM TZCLRLOCK bit: trip zone registers from 0x100 to 0x11A offsets locked selection
  [2] TZCFGLOCK — EPWM TZCFGLOCK bit: trip zone registers from 0x12E to 0x136 offsets locked selection
  [1] GLLOCK — EPWM GLLOCK bit: global load registers locked select
  [0] HRLOCK — EPWM HRLOCK bit: HRPWM registers locked select
0x3F4 HWVDELVAL ro — EPWM hareware valley delay register
  [15:0] HWVDELVAL — EPWM HWVDELVAL[15:0] bit: hardware valley delay value register
0x3F8 VCNTVAL ro — EPWM hareware valley counter register
  [15:0] VCNTVAL — EPWM VCNTVAL[15:0] bit: valley time base counter register
0x400 XCMPCTL1 — EPWM XCMP mode control register
  [11:8] XCMPBALLOC — EPWM XCMPBALLOC[3:0] bit: XCMPn register allocation for CMPB
  [7:4] XCMPAALLOC — EPWM XCMPAALLOC[3:0] bit: XCMPn register allocation for CMPA
  [1] XCMPSPLIT — EPWM XCMPSPLIT bit: XCMP register allocation options
  [0] XCMPEN — EPWM XCMPEN bit: XCMP compare register operation enable
0x420 XLOADCTL — EPWM XCMP mode load control register
  [30:28] RPTBUF3CNT ro — EPWM RPTBUF3CNT[2:0] bit: repeat count status shadow buffer 3
  [26:24] RPTBUF3PRD — EPWM RPTBUF3PRD[2:0] bit: repeat count shadow buffer 3
  [22:20] RPTBUF2CNT ro — EPWM RPTBUF2CNT[2:0] bit: repeat count status shadow buffer 2
  [18:16] RPTBUF2PRD — EPWM RPTBUF2PRD[2:0] bit: repeat count shadow buffer 2
  [11:10] HDWBUFPTRLOADMULTIPLE ro — EPWM HDWBUFPTRLOADMULTIPLE[1:0] bit: register load event count
  [9:8] SHDWBUFPTRLOADONCE — EPWM SHDWBUFPTRLOADONCE[1:0] bit: register load event count
  [5:4] SHDWLEVEL — EPWM SHDWLEVEL[1:0] bit: shadow register level allocation options
  [2] LOADMODE — EPWM LOADMODE bit: load mode selection for shadow registers
0x430 XLOAD — EPWM XCMP mode load register
  [1] FRCLD — EPWM FRCLD bit: force reload event in one shot mode
  [0] STARTLD — EPWM STARTLD bit: enable reload event
0x438 EPWMXLINKXLOAD — EPWM XLINK load register
  [4:0] XLOADLINK — EPWM XLOADLINK[4:0] bit: XLOAD link bits
{0x430+0x10*i} XREGSHDW{i}STS ro (i=1..3) — EPWM XREG shadow {i} state register
  [14] XMINSHDW{i}FULL — EPWM XMINSHDW{i}FULL bit: whether XMIN shadow {i} register is full
  [13] XMAXSHDW{i}FULL — EPWM XMAXSHDW{i}FULL bit: whether XMAX shadow {i} register is full
  [12] XAQCTLBSHDW{i}FULL — EPWM XAQCTLBSHDW{i}FULL bit: whether XAQCTLB shadow {i} register is full
  [11] XAQCTLASHDW{i}FULL — EPWM XAQCTLASHDW{i}FULL bit: whether XAQCTLA shadow {i} register is full
  [10] CMPDSHDW{i}FULL — EPWM CMPDSHDW{i}FULL bit: whether CMPD shadow {i} register is full
  [9] CMPCSHDW{i}FULL — EPWM CMPCSHDW{i}FULL bit: whether CMPC shadow {i} register is full
  [8] XTBPRDSHDW{i}FULL — EPWM XTBPRDSHDW{i}FULL bit: whether XTBPRD shadow {i} register is full
  [n-1] XCMP{n}SHDW{i}FULL (n=1..8) — EPWM XCMP{n}SHDW{i}FULL bit: whether XCMP{n} shadow {i} register is full
{0x478+8i} XCMP{i}ACTIVE (i=1..8) — EPWM XCMP active register {i}
  [31:16] XCMP{i}ACTIVE — EPWM XCMP{i}ACTIVE[15:0] bit: XCMP{i} active register
  [13:8] XCMP{i}HRACTIVE — EPWM XCMP{i}HRACTIVE[5:0] bit: XCMP{i}HR active register
0x4C0 XTBPRDACTIVE — EPWM XCMP time base period register
  [31:16] XTBPRDACTIVE — EPWM XTBPRDACTIVE[15:0] bit: XTBPRD active register
  [5:0] XTBPRDHRACTIVE — EPWM XTBPRDHRACTIVE [5:0] bit: XTBPRDHR active register
0x4D0 XAQCTLA — EPWM XAQCTLB active register
  [2n-1:2n-2] XCMP{n} (n=1..8) — EPWM XCMP{n}[1:0] bit: action when counter=CMP{n}
0x4D4 XAQCTLB — EPWM XAQCTLB active register
  [2n-1:2n-2] XCMP{n} (n=5..8) — EPWM XCMP{n}[1:0] bit: action when counter=CMP{n}
0x4F8 XMINMAXACTIVE — EPWM XMINMAX active register
  [31:16] XMINACTIVE — EPWM XMINACTIVE[15:0] bit: the XMIN active register value compare with threshold value of capture counter anytime
  [15:0] XMAXACTIVE — EPWM XMAXACTIVE[15:0] bit: the XMAX active register value compare with threshold value of capture counter anytime
{0x4F8+8i} XCMP{i}SHDW1 (i=1..8) — EPWM XCMP{i} shadow register 1
  [31:16] XCMP{i}SHDW1 — EPWM XCMP{i}SHDW1[15:0] bit: cache 1 register of XCMP{i} shadow register
  [13:8] XCMP{i}HRSHDW1 — EPWM XCMP{i}HRSHDW1[5:0] bit: cache 1 register of XCMP{i}HR shadow register
{0x4C0+0x80*i} XTBPRDSHDW{i} (i=1..3) — EPWM XCMP time base period shadow register {i}
  [31:16] XTBPRDSHDW{i} — EPWM XTBPRDSHDW{i}[15:0] bit: cache {i} register of XTBPRD shadow register
  [5:0] XTBPRDHRSHDW{i} — EPWM XTBPRDHRSHDW{i}[5:0] bit: cache {i} register of XTBPRDHR shadow register
{0x4D0+0x80*i} XAQCTLASHDW{i} (i=1..3) — EPWM XAQCTLA shadow register {i}
  fields as XAQCTLA
{0x4D4+0x80*i} XAQCTLBSHDW{i} (i=1..3) — EPWM XAQCTLB shadow register {i}
  fields as XAQCTLB
{0x4DC+0x80*i} CMPCSHDW{i} (i=1..3) — EPWM CMPC shadow register {i}
  [15:0] CMPCSHDW{i} — EPWM CMPCSHDW{i}[15:0] bit: cache {i} register of CMPC shadow register
{0x4E4+0x80*i} CMPDSHDW{i} (i=1..3) — EPWM CMPD shadow register {i}
  [15:0] CMPDSHDW{i} — EPWM CMPDSHDW{i}[15:0] bit: cache {i} register of CMPD shadow register
{0x4F8+0x80*i} XMINMAXSHDW{i} (i=1..3) — EPWM XMINMAX shadow register {i}
  [31:16] XMINSHDW{i} — EPWM XMINSHDW{i}[15:0] bit: cache {i} register of XMIN shadow register
  [15:0] XMAXSHDW{i} — EPWM XMAXSHDW{i}[15:0] bit: cache {i} register of XMAX shadow register
{0x578+8i} XCMP{i}SHDW2 (i=1..8) — EPWM XCMP{i} shadow register 2
  [31:16] XCMP{i}SHDW2 — EPWM XCMP{i}SHDW2[15:0] bit: cache 2 register of XCMP{i} shadow register
  [13:8] XCMP{i}HRSHDW2 — EPWM XCMP{i}HRSHDW2[5:0] bit: cache 2 register of XCMP{i}HR shadow register
{0x5F8+8i} XCMP{i}SHDW3 (i=1..8) — EPWM XCMP{i} shadow register 3
  [31:16] XCMP{i}SHDW3 — EPWM XCMP{i}SHDW3[15:0] bit: cache 3 register of XCMP{i} shadow register
  [13:8] XCMP{i}HRSHDW3 — EPWM XCMP{i}HRSHDW3[5:0] bit: cache 3 register of XCMP{i}HR shadow register
0x700 DECTL — EPWM DE control register
  [15:8] REENTRYDLY — EPWM REENTRYDLY[7:0] bit: determines the blocking window after DEACTIVE flag is cleared
  [1] MODE — EPWM MODE bit: DEACTIVE flag works mode select
  [0] ENABLE — EPWM ENABLE bit: DE function enable
0x708 DECOMPSEL — EPWM DE compare selection register
  [21:16] TRIPH — EPWM TRIPH[5:0] bit: determine the source of the TRIPH signal
  [5:0] TRIPL — EPWM TRIPL[5:0] bit: determine the source of the TRIPL signal
0x710 DEACTCTL — EPWM DE active register
  [16] TRIPENABLE — EPWM TRIPENABLE bit: TRIP enable
  [6] TRIPSELB — EPWM TRIPSELB bit: TRIP select PWMB
  [5:4] PWMB — EPWM PWMB[1:0] bit: PWMB control select bit
  [2] TRIPSELA — EPWM TRIPSELA bit: TRIP select PWMA
  [1:0] PWMA — EPWM PWMA[1:0] bit: PWMA control select bit
0x718 DESTS ro — EPWM DE state register
  [0] DEACTIVE — EPWM DEACTIVE bit: diode emulation mode activite select
0x720 DEFRC — EPWM DE software force register
  [0] DEACTIVE — EPWM DEACTIVE bit: force DEACTIVE flag
0x728 DECLR — EPWM DE state clear register
  [0] DEACTIVE — EPWM DEACTIVE bit: clears DEACTIVE flag
0x740 DEMONCNT ro — EPWM DE monitor counter register
  [15:0] CNT — EPWM CNT[15:0] bit: an 16-bit counter which monitors the frequency of diode mode trip events
0x748 DEMONCTL — EPWM DE monitor control register
  [0] ENABLE — EPWM ENABLE bit: enable bit for DE mode monitor counter function
0x750 DEMONSTEP — EPWM DE monitor step register
  [23:16] DECSTEP — EPWM DECSTEP[7:0] bit: defines the decrement step of DEMONCNT[CNT] counter
  [7:0] INCSTEP — EPWM INCSTEP[7:0] bit: defines the increment step of DEMONCNT[CNT] counter
0x758 DEMONTHRES — EPWM DE monitor threshold register
  [15:0] THRESHOLD — EPWM THRESHOLD[15:0] bit: defines the threshold of DE monitor counter
0x780 MINDBCFG — EPWM mini dead time config register
  [24] POLSELB — EPWM POLSELB bit: select signal for the AND OR logic of BLOCKB and PWMB signals
  [23:20] SELB — EPWM SELB[3:0] bit: PWMB min dead band reference
  [19] SELBLOCKB — EPWM SELBLOCKB bit: blocking signal on PWMB select
  [18] INVERTB — EPWM INVERTB bit: whether invert the selected reference signal on PWMB
  [16] ENABLEB — EPWM ENABLEB bit: minimum dead band logic enable select of PWMB
  [8] POLSELA — EPWM POLSELA bit: select signal for the AND OR logic of BLOCKA and PWMA signals
  [7:4] SELA — EPWM SELA[3:0] bit: PWMA min dead band reference
  [3] SELBLOCKA — EPWM SELBLOCKA bit: blocking signal on PWMB select
  [2] INVERTA — EPWM INVERTA bit: whether invert the selected reference signal on PWMA
  [0] ENABLEA — EPWM ENABLEA bit: minimum dead band logic enable select of PWMA
0x788 MINDBDLY — EPWM mini dead time delay register
  [31:16] DELAYB — EPWM DELAYB[15:0] bit: minimum dead band delay on PWMB in terms of SYSCLK cycles
  [15:0] DELAYA — EPWM DELAYA[15:0] bit: minimum dead band delay on PWMA in terms of SYSCLK cycles
0x7C0 LUTCTLA — EPWM LUT control register B
  [n+16] LUTDEC{n} (n=0..7) — EPWM LUTDEC{n} bit: LUTDEC{n} of PWMA
  [7:4] SELXBAR — EPWM SELXBAR[3:0] bit: selects one of the 16 outputs of ICL XBAR to feed into IN3 of LUTA
  [0] BYPASS — EPWM BYPASS bit: bypass LUT logic on PWMA enable
0x7C8 LUTCTLB — EPWM LUT control register B
  [n+16] LUTDEC{n} (n=0..7) — EPWM LUTDEC{n} bit: LUTDEC{n} of PWMB
  [7:4] SELXBAR — EPWM SELXBAR[3:0] bit: selects one of the 16 outputs of ICL XBAR to feed into IN3 of LUTB
  [0] BYPASS — EPWM BYPASS bit: bypass LUT logic on PWMB enable
